# NUC1263AE register map
File version: 1.0
Registers are 32-bit, read-write, reset 0x0 unless marked. A register's access mark holds for its fields unless they carry their own. Offsets are from the block's base; [hi:lo] are bit positions; {n}, {i} and the like mark numbered series; 'fields as' and 'values as' point back to an identical list.

## NMI — NMI Register Map
Base 0x50000300
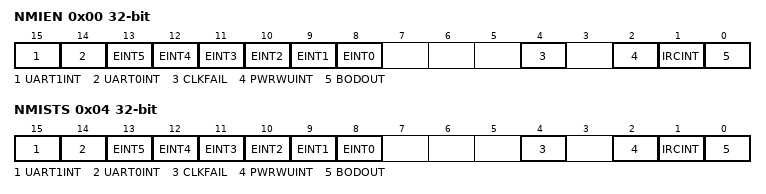
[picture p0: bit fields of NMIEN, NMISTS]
0x00 NMIEN — NMI Source Interrupt Enable Register
  [15] UART1INT — UART1 NMI Source Enable Bit (Write Protect). Note: This bit is write protected. Refer to the SYS_REGLCTL register.
    0=UART1 NMI source Disabled; 1=UART1 NMI source Enabled
  [14] UART0INT — UART0 NMI Source Enable Bit (Write Protect). Note: This bit is write protected. Refer to the SYS_REGLCTL register.
    0=UART0 NMI source Disabled; 1=UART0 NMI source Enabled
  [n+8] EINT{n} (n=0..5) — External Interrupt from INT{n} Pin NMI Source Enable Bit (Write Protect). Note: This bit is write protected. Refer to the SYS_REGLCTL register.
    0=External interrupt from INT{n} pin NMI source Disabled; 1=External interrupt from INT{n} pin NMI source Enabled
  [4] CLKFAIL — Clock Fail Detected NMI Source Enable Bit (Write Protect). Note: This bit is write protected. Refer to the SYS_REGLCTL register.
    0=Clock fail detected interrupt NMI source Disabled; 1=Clock fail detected interrupt NMI source Enabled
  [2] PWRWUINT — Power-down Mode Wake-up NMI Source Enable Bit (Write Protect). Note: This bit is write protected. Refer to the SYS_REGLCTL register.
    0=Power-down mode wake-up NMI source Disabled; 1=Power-down mode wake-up NMI source Enabled
  [1] IRCINT — IRC TRIM NMI Source Enable Bit (Write Protect). Note: This bit is write protected. Refer to the SYS_REGLCTL register.
    0=IRC TRIM NMI source Disabled; 1=IRC TRIM NMI source Enabled
  [0] BODOUT — BOD NMI Source Enable Bit (Write Protect). Note: This bit is write protected. Refer to the SYS_REGLCTL register.
    0=BOD NMI source Disabled; 1=BOD NMI source Enabled
0x04 NMISTS ro — NMI Source Interrupt Status Register
  [15] UART1INT — UART1 Interrupt Flag (Read Only)
    0=UART1 interrupt is deasserted; 1=UART1 interrupt is asserted
  [14] UART0INT — UART0 Interrupt Flag (Read Only)
    values as UART1INT
  [n+8] EINT{n} (n=0..5) — External Interrupt from INT{n} Pin Interrupt Flag (Read Only)
    0=External Interrupt from INT{n} pin interrupt is deasserted; 1=External Interrupt from INT{n} pin interrupt is asserted
  [4] CLKFAIL — Clock Fail Detected Interrupt Flag (Read Only)
    0=Clock fail detected interrupt is deasserted; 1=Clock fail detected interrupt is asserted
  [2] PWRWUINT — Power-down Mode Wake-up Interrupt Flag (Read Only)
    0=Power-down mode wake-up interrupt is deasserted; 1=Power-down mode wake-up interrupt is asserted
  [1] IRCINT — IRC TRIM Interrupt Flag (Read Only)
    0=HIRC TRIM interrupt is deasserted; 1=HIRC TRIM interrupt is asserted
  [0] BODOUT — BOD Interrupt Flag (Read Only)
    0=BOD interrupt is deasserted; 1=BOD interrupt is asserted

## WWDT — WWDT Register Map
Base 0x40004100
0x00 WWDT_RLDCNT wo — WWDT Reload Counter Register
  [31:0] RLDCNT — WWDT Reload Counter Register. Writing only 0x00005AA5 to this register will reload the WWDT counter value to 0x3F. Note 1: User can only execute the reload WWDT counter value command when current CNTDAT (WWDT_CNT[5:0]) is between 1 and CMPDAT (WWDT_CTL[21:16]). If user writes 0x00005AA5 in WWDT_RLDCNT register when the current CNTDAT is greater than CMPDAT, WWDT reset system event will be generated immediately. Note 2: Executing WWDT counter reload always needs (WWDT_CLK *3) period to reload CNTDAT to 0x3F and internal prescale counter will be reset also.
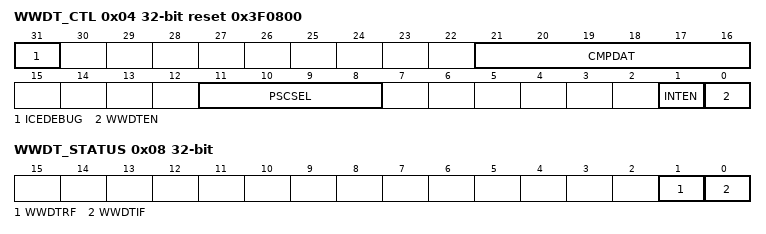
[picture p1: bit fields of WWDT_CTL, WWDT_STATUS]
0x04 WWDT_CTL reset 0x3F0800 — WWDT Control Register
  [31] ICEDEBUG — ICE Debug Mode Acknowledge Disable Bit. The WWDT down counter will keep counting no matter CPU is held by ICE or not.
    0=ICE debug mode acknowledgement effects WWDT counter counting; 1=ICE debug mode acknowledgement Disabled
  [21:16] CMPDAT — WWDT Window Compare Value. Set this field to adjust the valid reload window interval when WWDTIF (WWDT_STATUS[0]) is generated. Note: User can only write WWDT_RLDCNT register to reload WWDT counter value when current CNTDAT (WWDT_CNT[5:0]) is between 1 and CMPDAT. If user writes 0x00005AA5 in WWDT_RLDCNT register when the current CNTDAT is greater than CMPDAT, WWDT reset system event will be generated immediately.
  [11:8] PSCSEL — WWDT Counter Prescale Period Selection
    0=Pre-scale is 1; Max time-out period is 1 * 64 * WWDT_CLK; 1=Pre-scale is 2; Max time-out period is 2 * 64 * WWDT_CLK; 2=Pre-scale is 4; Max time-out period is 4 * 64 * WWDT_CLK; 3=Pre-scale is 8; Max time-out period is 8 * 64 * WWDT_CLK; 4=Pre-scale is 16; Max time-out period is 16 * 64 * WWDT_CLK; 5=Pre-scale is 32; Max time-out period is 32 * 64 * WWDT_CLK; 6=Pre-scale is 64; Max time-out period is 64 * 64 * WWDT_CLK; 7=Pre-scale is 128; Max time-out period is 128 * 64 * WWDT_CLK; 8=Pre-scale is 192; Max time-out period is 192 * 64 * WWDT_CLK; 9=Pre-scale is 256; Max time-out period is 256 * 64 * WWDT_CLK; 10=Pre-scale is 384; Max time-out period is 384 * 64 * WWDT_CLK; 11=Pre-scale is 512; Max time-out period is 512 * 64 * WWDT_CLK; 12=Pre-scale is 768; Max time-out period is 768 * 64 * WWDT_CLK; 13=Pre-scale is 1024; Max time-out period is 1024 * 64 * WWDT_CLK; 14=Pre-scale is 1536; Max time-out period is 1536 * 64 * WWDT_CLK; 15=Pre-scale is 2048; Max time-out period is 2048 * 64 * WWDT_CLK
  [1] INTEN — WWDT Interrupt Enable Bit. If this bit is enabled, when WWDTIF (WWDT_STATUS[0]) is set to 1, the WWDT counter compare match interrupt signal is generated and inform to CPU.
    0=WWDT counter compare match interrupt disabled; 1=WWDT counter compare match interrupt enabled
  [0] WWDTEN — WWDT Enable Bit. Set this bit to start WWDT counter counting.
    0=WWDT counter is stopped; 1=WWDT counter is starting counting
0x08 WWDT_STATUS
  [1] WWDTRF — WWDT Timer-out Reset System Flag. If this bit is set to 1, it indicates that system has been reset by WWDT counter time-out reset system event. Note: This bit is cleared by writing 1 to it.
    0=WWDT time-out reset system event did not occur; 1=WWDT time-out reset system event occurred
  [0] WWDTIF — WWDT Compare Match Interrupt Flag. This bit indicates that current CNTDAT (WWDT_CNT[5:0]) matches the CMPDAT (WWDT_CTL[21:16]). Note: This bit is cleared by writing 1 to it.
    0=No effect; 1=WWDT CNTDAT matches the CMPDAT
0x0C WWDT_CNT ro reset 0x3F — WWDT Counter Value Register
  [5:0] CNTDAT — WWDT Counter Value. CNTDAT will be updated continuously.
